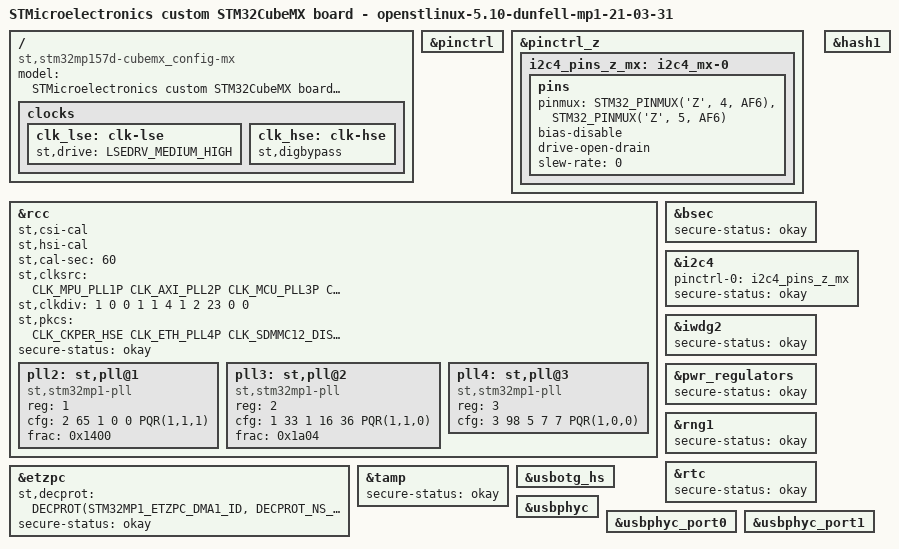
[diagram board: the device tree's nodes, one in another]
/* SPDX-License-Identifier: (GPL-2.0+ OR BSD-3-Clause) */
/*
 * Copyright (C) STMicroelectronics 2021 - All Rights Reserved
 * Author: STM32CubeMX code generation for STMicroelectronics.
 */

/* For more information on Device Tree configuration, please refer to
 * https://wiki.st.com/stm32mpu/wiki/Category:Device_tree_configuration
 */

/dts-v1/;
#include <dt-bindings/pinctrl/stm32-pinfunc.h>
#include <dt-bindings/clock/stm32mp1-clksrc.h>
#include <dt-bindings/soc/st,stm32-etzpc.h>
#include "stm32mp15-mx.dtsi"

#include "stm32mp157.dtsi"
#include "stm32mp15xd.dtsi"
#include "stm32mp15xxaa-pinctrl.dtsi"
#include "stm32mp15-ddr.dtsi"

/* USER CODE BEGIN includes */
/* USER CODE END includes */

/ {
	model = "STMicroelectronics custom STM32CubeMX board - openstlinux-5.10-dunfell-mp1-21-03-31";
	compatible = "st,stm32mp157d-cubemx_config-mx", "st,stm32mp157";

	/* USER CODE BEGIN root */
	/* USER CODE END root */

	clocks {
		/* USER CODE BEGIN clocks */
		/* USER CODE END clocks */

		clk_lse: clk-lse {
			st,drive = < LSEDRV_MEDIUM_HIGH >;

			/* USER CODE BEGIN clk_lse */
			/* USER CODE END clk_lse */
		};

		clk_hse: clk-hse {
			st,digbypass;

			/* USER CODE BEGIN clk_hse */
			/* USER CODE END clk_hse */
		};
	};

}; /*root*/

&pinctrl {
	/* USER CODE BEGIN pinctrl */
	/* USER CODE END pinctrl */
};

&pinctrl_z {
	i2c4_pins_z_mx: i2c4_mx-0 {
		pins {
			pinmux = <STM32_PINMUX('Z', 4, AF6)>, /* I2C4_SCL */
					 <STM32_PINMUX('Z', 5, AF6)>; /* I2C4_SDA */
			bias-disable;
			drive-open-drain;
			slew-rate = <0>;
		};
	};

	/* USER CODE BEGIN pinctrl_z */
	/* USER CODE END pinctrl_z */
};

&rcc {
	st,csi-cal;
	st,hsi-cal;
	st,cal-sec = <60>;
	st,clksrc = <
		CLK_MPU_PLL1P
		CLK_AXI_PLL2P
		CLK_MCU_PLL3P
		CLK_PLL12_HSE
		CLK_PLL3_HSE
		CLK_PLL4_HSE
		CLK_RTC_LSE
		CLK_MCO1_DISABLED
		CLK_MCO2_DISABLED
	>;
	st,clkdiv = <
		1 		/*MPU*/
		0 		/*AXI*/
		0 		/*MCU*/
		1 		/*APB1*/
		1 		/*APB2*/
		4 		/*APB3*/
		1 		/*APB4*/
		2 		/*APB5*/
		23 		/*RTC*/
		0 		/*MCO1*/
		0 		/*MCO2*/
	>;
	st,pkcs = <
		CLK_CKPER_HSE
		CLK_ETH_PLL4P
		CLK_SDMMC12_DISABLED
		CLK_STGEN_HSE
		CLK_USBPHY_HSE
		CLK_SPI2S1_PLL4P
		CLK_SPI2S23_DISABLED
		CLK_SPI45_DISABLED
		CLK_SPI6_DISABLED
		CLK_I2C46_HSI
		CLK_SDMMC3_DISABLED
		CLK_USBO_USBPHY
		CLK_ADC_CKPER
		CLK_CEC_LSE
		CLK_I2C12_HSI
		CLK_I2C35_PCLK1
		CLK_UART1_DISABLED
		CLK_UART24_DISABLED
		CLK_UART35_PCLK1
		CLK_UART6_DISABLED
		CLK_UART78_DISABLED
		CLK_SPDIF_DISABLED
		CLK_SAI1_DISABLED
		CLK_SAI2_PLL3Q
		CLK_SAI3_DISABLED
		CLK_SAI4_DISABLED
		CLK_RNG1_LSI
		CLK_LPTIM1_DISABLED
		CLK_LPTIM23_DISABLED
		CLK_LPTIM45_DISABLED
	>;
	pll2:st,pll@1 {
		compatible = "st,stm32mp1-pll";
		reg = <1>;
		cfg = < 2 65 1 0 0 PQR(1,1,1) >;
		frac = < 0x1400 >;
	};
	pll3:st,pll@2 {
		compatible = "st,stm32mp1-pll";
		reg = <2>;
		cfg = < 1 33 1 16 36 PQR(1,1,0) >;
		frac = < 0x1a04 >;
	};
	pll4:st,pll@3 {
		compatible = "st,stm32mp1-pll";
		reg = <3>;
		cfg = < 3 98 5 7 7 PQR(1,0,0) >;
	};
};

&bsec{
	status = "okay";
	secure-status = "okay";

	/* USER CODE BEGIN bsec */
	/* USER CODE END bsec */
};

&etzpc{
	st,decprot = <
	/*"Non Secured" peripherals*/
	DECPROT(STM32MP1_ETZPC_DMA1_ID, DECPROT_NS_RW, DECPROT_UNLOCK)
	DECPROT(STM32MP1_ETZPC_DMAMUX_ID, DECPROT_NS_RW, DECPROT_UNLOCK)
	DECPROT(STM32MP1_ETZPC_ETH_ID, DECPROT_NS_RW, DECPROT_UNLOCK)
	DECPROT(STM32MP1_ETZPC_HASH1_ID, DECPROT_NS_RW, DECPROT_UNLOCK)
	DECPROT(STM32MP1_ETZPC_CEC_ID, DECPROT_NS_RW, DECPROT_UNLOCK)
	DECPROT(STM32MP1_ETZPC_I2C1_ID, DECPROT_NS_RW, DECPROT_UNLOCK)
	DECPROT(STM32MP1_ETZPC_I2C4_ID, DECPROT_NS_RW, DECPROT_UNLOCK)
	DECPROT(STM32MP1_ETZPC_RNG1_ID, DECPROT_NS_RW, DECPROT_UNLOCK)
	DECPROT(STM32MP1_ETZPC_SAI2_ID, DECPROT_NS_RW, DECPROT_UNLOCK)
	DECPROT(STM32MP1_ETZPC_OTG_ID, DECPROT_NS_RW, DECPROT_UNLOCK)
	DECPROT(STM32MP1_ETZPC_VREFBUF_ID, DECPROT_NS_RW, DECPROT_UNLOCK)
	/*"NS_R S_W" peripherals*/
	DECPROT(STM32MP1_ETZPC_DDRCTRL_ID, DECPROT_NS_R_S_W, DECPROT_LOCK)
	DECPROT(STM32MP1_ETZPC_DDRPHYC_ID, DECPROT_NS_R_S_W, DECPROT_LOCK)
	/*"Secured" peripherals*/
	DECPROT(STM32MP1_ETZPC_STGENC_ID, DECPROT_S_RW, DECPROT_UNLOCK)
	/*"Mcu Isolation" peripherals*/
	DECPROT(STM32MP1_ETZPC_ADC_ID, DECPROT_MCU_ISOLATION, DECPROT_UNLOCK)
	DECPROT(STM32MP1_ETZPC_DAC_ID, DECPROT_MCU_ISOLATION, DECPROT_UNLOCK)
	DECPROT(STM32MP1_ETZPC_DMA2_ID, DECPROT_MCU_ISOLATION, DECPROT_UNLOCK)
	DECPROT(STM32MP1_ETZPC_I2C5_ID, DECPROT_MCU_ISOLATION, DECPROT_UNLOCK)
	DECPROT(STM32MP1_ETZPC_SPI1_ID, DECPROT_MCU_ISOLATION, DECPROT_UNLOCK)
	DECPROT(STM32MP1_ETZPC_TIM1_ID, DECPROT_MCU_ISOLATION, DECPROT_UNLOCK)
	DECPROT(STM32MP1_ETZPC_TIM2_ID, DECPROT_MCU_ISOLATION, DECPROT_UNLOCK)
	DECPROT(STM32MP1_ETZPC_TIM6_ID, DECPROT_MCU_ISOLATION, DECPROT_UNLOCK)
	DECPROT(STM32MP1_ETZPC_TIM7_ID, DECPROT_MCU_ISOLATION, DECPROT_UNLOCK)
	DECPROT(STM32MP1_ETZPC_TIM8_ID, DECPROT_MCU_ISOLATION, DECPROT_UNLOCK)
	DECPROT(STM32MP1_ETZPC_UART5_ID, DECPROT_MCU_ISOLATION, DECPROT_UNLOCK)
	DECPROT(STM32MP1_ETZPC_USART3_ID, DECPROT_MCU_ISOLATION, DECPROT_UNLOCK)
	DECPROT(STM32MP1_ETZPC_WWDG1_ID, DECPROT_MCU_ISOLATION, DECPROT_UNLOCK)

	/*Restriction: following IDs are not managed  - please to use User-Section if needed:
		STM32MP1_ETZPC_SRAMx_ID, STM32MP1_ETZPC_RETRAM_ID, STM32MP1_ETZPC_BKPSRAM_ID*/

	/* USER CODE BEGIN etzpc_decprot */
		/*STM32CubeMX generates a basic and standard configuration for ETZPC.
		Additional device configurations can be added here if needed.
		"etzpc" node could be also overloaded in "addons" User-Section.*/
	/* USER CODE END etzpc_decprot */
	>;

	secure-status = "okay";

	/* USER CODE BEGIN etzpc */
	/* USER CODE END etzpc */
};

&hash1{
	status = "okay";

	/* USER CODE BEGIN hash1 */
	/* USER CODE END hash1 */
};

&i2c4{
	pinctrl-names = "default";
	pinctrl-0 = <&i2c4_pins_z_mx>;
	status = "okay";
	secure-status = "okay";

	/* USER CODE BEGIN i2c4 */
	/* USER CODE END i2c4 */
};

&iwdg2{
	status = "okay";
	secure-status = "okay";

	/* USER CODE BEGIN iwdg2 */
	/* USER CODE END iwdg2 */
};

&pwr_regulators{
	status = "okay";
	secure-status = "okay";

	/* USER CODE BEGIN pwr_regulators */
	/* USER CODE END pwr_regulators */
};

&rcc{
	status = "okay";
	secure-status = "okay";

	/* USER CODE BEGIN rcc */
	/* USER CODE END rcc */
};

&rng1{
	status = "okay";
	secure-status = "okay";

	/* USER CODE BEGIN rng1 */
	/* USER CODE END rng1 */
};

&rtc{
	status = "okay";
	secure-status = "okay";

	/* USER CODE BEGIN rtc */
	/* USER CODE END rtc */
};

&tamp{
	status = "okay";
	secure-status = "okay";

	/* USER CODE BEGIN tamp */
	/* USER CODE END tamp */
};

&usbotg_hs{
	status = "okay";

	/* USER CODE BEGIN usbotg_hs */
	/* USER CODE END usbotg_hs */
};

&usbphyc{
	status = "okay";

	/* USER CODE BEGIN usbphyc */
	/* USER CODE END usbphyc */
};

&usbphyc_port0{
	status = "okay";

	/* USER CODE BEGIN usbphyc_port0 */
	/* USER CODE END usbphyc_port0 */
};

&usbphyc_port1{
	status = "okay";

	/* USER CODE BEGIN usbphyc_port1 */
	/* USER CODE END usbphyc_port1 */
};

/* USER CODE BEGIN addons */
/* USER CODE END addons */

